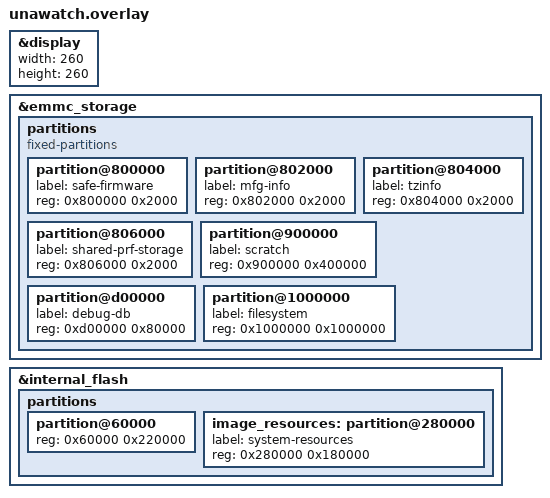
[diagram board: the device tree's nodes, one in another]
// SPDX-FileCopyrightText: 2026 The unapebble authors
// SPDX-License-Identifier: Apache-2.0

// The firmware's storage, on the eMMC, in the 32 MiB window of its GUI region the board gives it
// (unawatch.dts): offsets are from the start of the window, 200 MiB into the eMMC. The bootloader
// leaves the region alone, so the filesystem and the logs survive an update. The system resources
// come with the image, in the embedded flash (CONFIG_RESOURCES_IN_CODE_FLASH).
//
// The window is read and written in 512-byte blocks, as NOR flash in 4 KiB subsectors and 64 KiB
// sectors: every partition is a whole number of subsectors, the filesystem of sectors. What the
// partitions leave of the window is free, among it the first 8 MiB, where earlier builds kept
// the resources: the partitions after it stay where they were, and so does what they hold.

// The gabbro platform's 260 x 260 framebuffer, of which the 240 x 240 panel shows the centre
&display {
	width = <260>;
	height = <260>;
};

&emmc_storage {
	partitions {
		compatible = "fixed-partitions";
		#address-cells = <1>;
		#size-cells = <1>;

		// Only protected: there is no recovery firmware to keep
		partition@800000 {
			label = "safe-firmware";
			reg = <0x800000 0x2000>;
		};

		partition@802000 {
			label = "mfg-info";
			reg = <0x802000 0x2000>;
		};

		partition@804000 {
			label = "tzinfo";
			reg = <0x804000 0x2000>;
		};

		partition@806000 {
			label = "shared-prf-storage";
			reg = <0x806000 0x2000>;
		};

		// Core dumps, which take the RAM in use
		partition@900000 {
			label = "scratch";
			reg = <0x900000 0x400000>;
		};

		// As large as the flash log goes: fewer than 256 pages of 4 KiB
		partition@d00000 {
			label = "debug-db";
			reg = <0xd00000 0x80000>;
		};

		partition@1000000 {
			label = "filesystem";
			reg = <0x1000000 0x1000000>;
		};
	};
};

// The embedded flash: the code, then the system resources installed with it at a fixed place
// (pebbleos_resources.bin), up to the end of the 4 MiB, which the bootloader erases and writes
// from 0x08060000 on every install. Both in 8 KiB pages.
&internal_flash {
	partitions {
		// 2176 KiB
		partition@60000 {
			reg = <0x60000 0x220000>;
		};

		// 1536 KiB, for about 0.9 MiB of resources, read in place
		image_resources: partition@280000 {
			label = "system-resources";
			reg = <0x280000 0x180000>;
		};
	};
};
